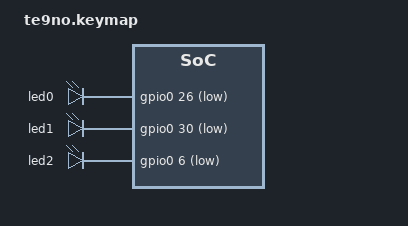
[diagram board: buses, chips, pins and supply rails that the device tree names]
/*
 * Copyright (c) 2022 The ZMK Contributors
 *
 * SPDX-License-Identifier: MIT
 */

#include <behaviors.dtsi>
#include <dt-bindings/zmk/keys.h>
#include <dt-bindings/zmk/bt.h>

/ {
    keymap {
        compatible = "zmk,keymap";

        default_layer {
            bindings = <
                &kp X
                &kp Z
            >;
        };
    };
};

/ {
    aliases {
        led-red = &led0;
        led-green = &led1;
        led-blue = &led2;
    };

    leds {
        compatible = "gpio-leds";
        status = "okay";
        led0: led_0 {
            gpios = <&gpio0 26 GPIO_ACTIVE_LOW>;  // red LED, connected to P0.26
        };
        led1: led_1 {
            gpios = <&gpio0 30 GPIO_ACTIVE_LOW>;  // green LED, connected to P0.30
        };
        led2: led_2 {
            gpios = <&gpio0 6 GPIO_ACTIVE_LOW>;  // blue LED, connected to P0.06
        };
    };
};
